# R7FA6T2BD register map
Vendor: Renesas Electronics Corporation; Series: RA6; File version: 1.30.01
CPU: CM33 r0p4, little endian, MPU, FPU, VTOR, 4 interrupt priority bits, 96 interrupts
Registers are 32-bit, read-write, reset 0x0 unless marked. A register's access mark holds for its fields unless they carry their own. Offsets are from the block's base; [hi:lo] are bit positions; {n}, {i} and the like mark numbered series.

## KINT — Key Interrupt Function
Base 0x40085000
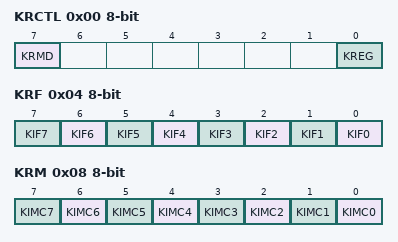
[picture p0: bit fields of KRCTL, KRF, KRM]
0x00 KRCTL 8-bit — Key Return Control Register
  [7] KRMD — Usage of Key Interrupt Flags (KRF.KIF0 to KRF.KIF7)
    0=Do not use key interrupt flags; 1=Use key interrupt flags
  [0] KREG — Detection Edge Selection (KR00 to KR07 pins)
    0=Falling edge; 1=Rising edge
0x04 KRF 8-bit — Key Return Flag Register
  [all] fields
    0=No interrupt detected; 1=Interrupt detected
  [n] KIF{n} (n=0..7) — Key Interrupt Flag n
0x08 KRM 8-bit — Key Return Mode Register
  [all] fields
    0=Do not detect key interrupt signals; 1=Detect key interrupt signals
  [n] KIMC{n} (n=0..7) — Key Interrupt Mode Control n

## AGTW_B0 — Low Power Asynchronous General Purpose Timer 0
Base 0x400E8000
Same registers: AGTW_B1 0x400E8100
0x00 AGT reset 0xFFFFFFFF — AGT Counter Register
0x04 AGTCMA reset 0xFFFFFFFF — AGT CounterCompare Match A Register
0x08 AGTCMB reset 0xFFFFFFFF — AGT CounterCompare Match B Register
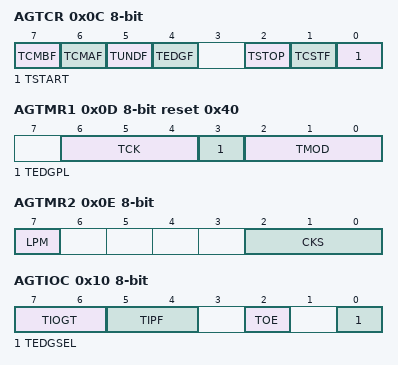
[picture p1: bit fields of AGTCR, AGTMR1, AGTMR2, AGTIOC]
0x0C AGTCR 8-bit — AGT Control Register
  [7] TCMBF — Compare Match B Flag
    0=No match; 1=Match
  [6] TCMAF — Compare Match A Flag
    0=No match; 1=Match
  [5] TUNDF — Underflow Flag
    0=No underflow; 1=Underflow
  [4] TEDGF — Active Edge Judgment Flag
    0=No active edge received; 1=Active edge received
  [2] TSTOP wo — AGT Count Forced Stop
    0=Writing is invalid; 1=The count is forcibly stopped
  [1] TCSTF ro — AGT Count Status Flag
    0=Count stopped; 1=Count in progress
  [0] TSTART — AGT Count Start
    0=Count stops; 1=Count starts
0x0D AGTMR1 8-bit reset 0x40 — AGT Mode Register 1
  [6:4] TCK — Count Source
    0=PCLKB; 1=PCLKB/8; 3=PCLKB/2; 4=Divided clock AGTLCLK specified by CKS[2:0] bits in the AGTMR2 register; 5=Underflow event signal from AGTW0; 6=Setting prohibited; other=Others (Setting prohibited)
  [3] TEDGPL — Edge Polarity
    0=Single-edge; 1=Both-edge
  [2:0] TMOD — Operating Mode
    0=Timer mode; 1=Pulse output mode; 2=Event counter mode; 3=Pulse width measurement mode; 4=Pulse period measurement mode; other=Others (Setting prohibited)
0x0E AGTMR2 8-bit — AGT Mode Register 2
  [7] LPM — Low Power Mode
    0=Normal mode; 1=Low power mode
  [2:0] CKS — AGTLCLK Count Source Clock Frequency Division Ratio
    0=1/1; 1=1/2; 2=1/4; 3=1/8; 4=1/16; 5=1/32; 6=1/64; 7=1/128
0x10 AGTIOC 8-bit — AGT I/O Control Register
  [7:6] TIOGT — Count Control
    0=Event is always counted; 1=Event is counted during polarity period specified for AGTWEEn pin; other=Others (Setting prohibited)
  [5:4] TIPF — Input Filter
    0=No filter; 1=Filter sampled at PCLKB; 2=Filter sampled at PCLKB/8; 3=Filter sampled at PCLKB/32
  [2] TOE — AGTWOn pin Output Enable
    0=AGTWOn pin output disabled; 1=AGTWOn pin output enabled
  [0] TEDGSEL — I/O Polarity Switch
0x11 AGTISR 8-bit — AGT Event Pin Select Register
  [2] EEPS — AGTWEEn Polarity Selection
    0=An event is counted during the low-level period; 1=An event is counted during the high-level period
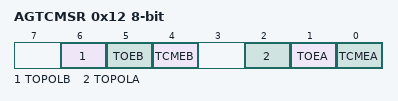
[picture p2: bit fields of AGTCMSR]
0x12 AGTCMSR 8-bit — AGT Compare Match Function Select Register
  [6] TOPOLB — AGTWOBn Pin Polarity Select
    0=AGTWOBn pin output is started on low. i.e. normal output; 1=AGTWOBn pin output is started on high. i.e. inverted output
  [5] TOEB — AGTWOBn Pin Output Enable
    0=AGTWOBn pin output disabled; 1=AGTWOBn pin output enabled
  [4] TCMEB — AGT Compare Match B Register Enable
    0=Compare match B register disabled; 1=Compare match B register enabled
  [2] TOPOLA — AGTWOAn Pin Polarity Select
    0=AGTWOAn pin output is started on low. i.e. normal output; 1=AGTWOAn pin output is started on high. i.e. inverted output
  [1] TOEA — AGTWOAn Pin Output Enable
    0=AGTWOAn pin output disabled; 1=AGTWOAn pin output enabled
  [0] TCMEA — AGT Compare Match A Register Enable
    0=AGT Compare match A register disabled; 1=AGT Compare match A register enabled
0x13 AGTIOSEL 8-bit — AGT Pin Select Register
  [4] TIES — AGTWIOn Pin Input Enable
    0=External event input is disabled during Software Standby mode; 1=External event input is enabled during Software Standby mode
